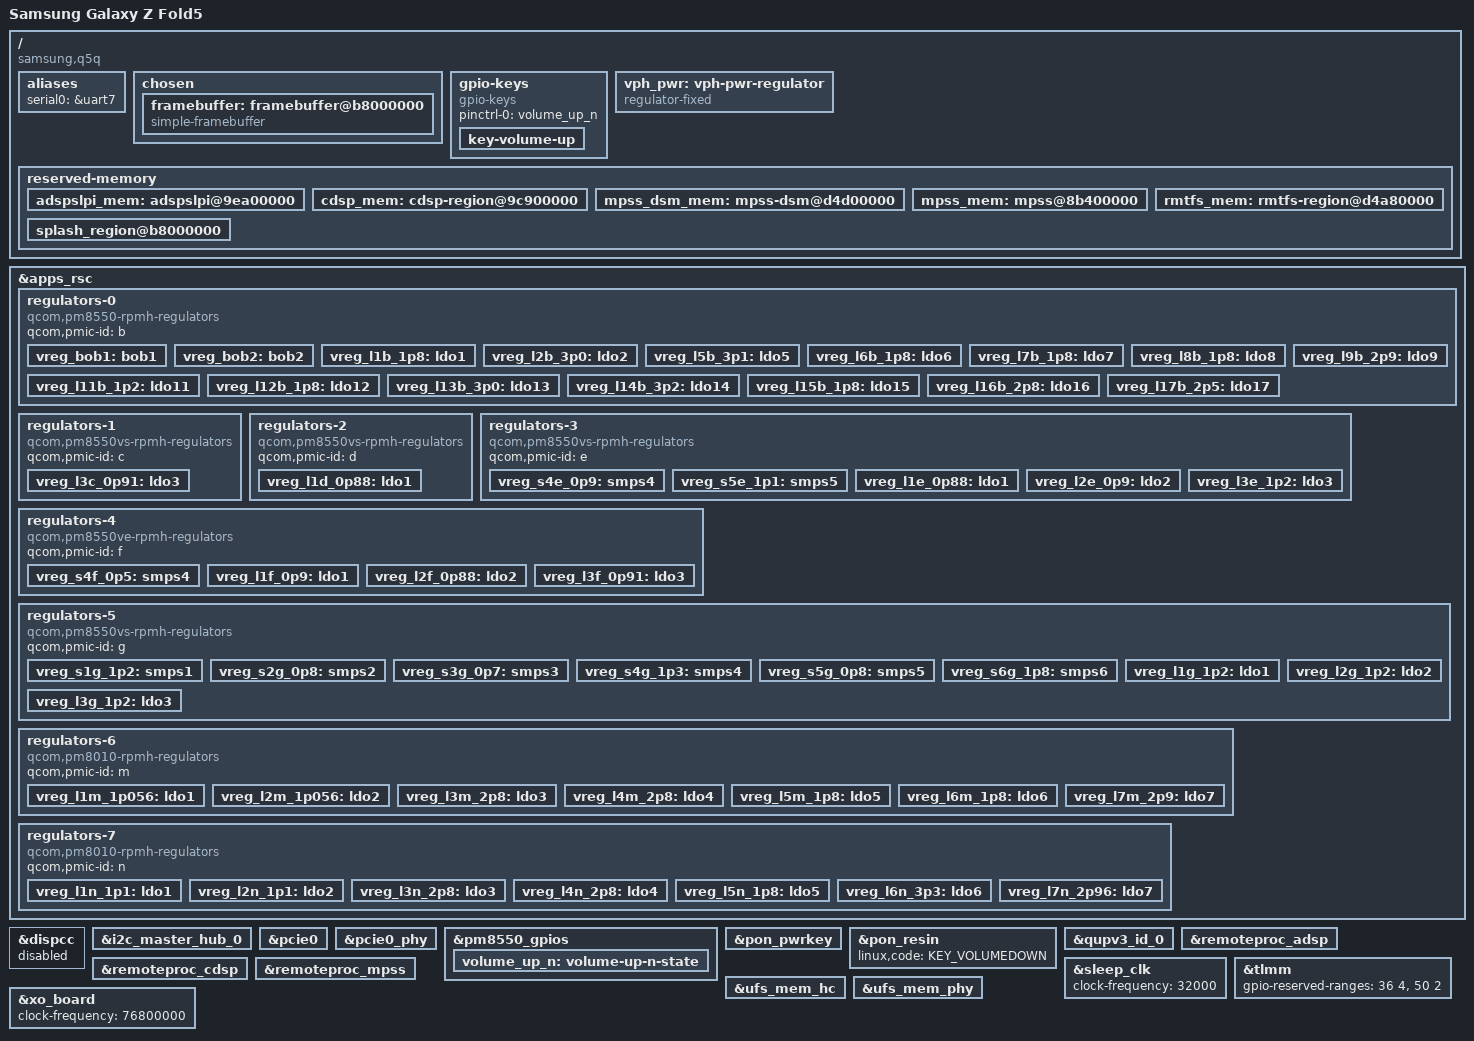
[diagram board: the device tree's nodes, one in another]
// SPDX-License-Identifier: BSD-3-Clause
/*
 * Copyright (c) 2024, Alexandru Marc Serdeliuc <serdeliuk@yahoo.com>
 * Copyright (c) 2024, David Wronek <david@mainlining.org>
 * Copyright (c) 2022, Linaro Limited
 */

/dts-v1/;

#include <dt-bindings/pinctrl/qcom,pmic-gpio.h>
#include <dt-bindings/regulator/qcom,rpmh-regulator.h>
#include "sm8550.dtsi"
#include "pm8550.dtsi"
#include "pm8550vs.dtsi"
#include "pmk8550.dtsi"

/delete-node/ &adspslpi_mem;
/delete-node/ &cdsp_mem;
/delete-node/ &mpss_dsm_mem;
/delete-node/ &mpss_mem;
/delete-node/ &rmtfs_mem;

/ {
	model = "Samsung Galaxy Z Fold5";
	compatible = "samsung,q5q", "qcom,sm8550";
	chassis-type = "handset";

	aliases {
		serial0 = &uart7;
	};

	chosen {
		#address-cells = <2>;
		#size-cells = <2>;
		ranges;

		framebuffer: framebuffer@b8000000 {
			compatible = "simple-framebuffer";
			reg = <0x0 0xb8000000 0x0 0x2b00000>;
			width = <2176>;
			height = <1812>;
			stride = <(2176 * 4)>;
			format = "a8r8g8b8";
		};
	};

	gpio-keys {
		compatible = "gpio-keys";
		pinctrl-0 = <&volume_up_n>;
		pinctrl-names = "default";

		key-volume-up {
			label = "Volume Up";
			linux,code = <KEY_VOLUMEUP>;
			gpios = <&pm8550_gpios 6 GPIO_ACTIVE_LOW>;
			debounce-interval = <15>;
			linux,can-disable;
			wakeup-source;
		};
	};

	vph_pwr: vph-pwr-regulator {
		compatible = "regulator-fixed";
		regulator-name = "vph_pwr";
		regulator-min-microvolt = <3700000>;
		regulator-max-microvolt = <3700000>;
		regulator-always-on;
		regulator-boot-on;
	};

	reserved-memory {
		adspslpi_mem: adspslpi@9ea00000 {
			reg = <0x0 0x9ea00000 0x0 0x59b4000>;
			no-map;
		};

		cdsp_mem: cdsp-region@9c900000 {
			reg = <0 0x9c900000 0 0x2000000>;
			no-map;
		};

		mpss_dsm_mem: mpss-dsm@d4d00000 {
			reg = <0x0 0xd4d00000 0x0 0x3300000>;
			no-map;
		};

		mpss_mem: mpss@8b400000 {
			reg = <0x0 0x8b400000 0x0 0xfc00000>;
			no-map;
		};

		rmtfs_mem: rmtfs-region@d4a80000 {
			reg = <0x0 0xd4a80000 0x0 0x280000>;
			no-map;
		};

		/*
		 * The bootloader will only keep display hardware enabled
		 * if this memory region is named exactly 'splash_region'
		 */
		splash_region@b8000000 {
			reg = <0x0 0xb8000000 0x0 0x2b00000>;
			no-map;
		};
	};
};

&apps_rsc {
	regulators-0 {
		compatible = "qcom,pm8550-rpmh-regulators";
		qcom,pmic-id = "b";

		vreg_bob1: bob1 {
			regulator-name = "vreg_bob1";
			regulator-min-microvolt = <3296000>;
			regulator-max-microvolt = <3960000>;
			regulator-initial-mode = <RPMH_REGULATOR_MODE_HPM>;
		};

		vreg_bob2: bob2 {
			regulator-name = "vreg_bob2";
			regulator-min-microvolt = <2720000>;
			regulator-max-microvolt = <3960000>;
			regulator-initial-mode = <RPMH_REGULATOR_MODE_HPM>;
		};

		vreg_l1b_1p8: ldo1 {
			regulator-name = "vreg_l1b_1p8";
			regulator-min-microvolt = <1800000>;
			regulator-max-microvolt = <1800000>;
			regulator-initial-mode = <RPMH_REGULATOR_MODE_HPM>;
		};

		vreg_l2b_3p0: ldo2 {
			regulator-name = "vreg_l2b_3p0";
			regulator-min-microvolt = <3008000>;
			regulator-max-microvolt = <3008000>;
			regulator-initial-mode = <RPMH_REGULATOR_MODE_HPM>;
		};

		vreg_l5b_3p1: ldo5 {
			regulator-name = "vreg_l5b_3p1";
			regulator-min-microvolt = <3104000>;
			regulator-max-microvolt = <3104000>;
			regulator-initial-mode = <RPMH_REGULATOR_MODE_HPM>;
		};

		vreg_l6b_1p8: ldo6 {
			regulator-name = "vreg_l6b_1p8";
			regulator-min-microvolt = <1800000>;
			regulator-max-microvolt = <3008000>;
			regulator-initial-mode = <RPMH_REGULATOR_MODE_HPM>;
		};

		vreg_l7b_1p8: ldo7 {
			regulator-name = "vreg_l7b_1p8";
			regulator-min-microvolt = <1800000>;
			regulator-max-microvolt = <3008000>;
			regulator-initial-mode = <RPMH_REGULATOR_MODE_HPM>;
		};

		vreg_l8b_1p8: ldo8 {
			regulator-name = "vreg_l8b_1p8";
			regulator-min-microvolt = <1800000>;
			regulator-max-microvolt = <3008000>;
			regulator-initial-mode = <RPMH_REGULATOR_MODE_HPM>;
		};

		vreg_l9b_2p9: ldo9 {
			regulator-name = "vreg_l9b_2p9";
			regulator-min-microvolt = <2960000>;
			regulator-max-microvolt = <3008000>;
			regulator-initial-mode = <RPMH_REGULATOR_MODE_HPM>;
		};

		vreg_l11b_1p2: ldo11 {
			regulator-name = "vreg_l11b_1p2";
			regulator-min-microvolt = <1200000>;
			regulator-max-microvolt = <1504000>;
			regulator-initial-mode = <RPMH_REGULATOR_MODE_HPM>;
		};

		vreg_l12b_1p8: ldo12 {
			regulator-name = "vreg_l12b_1p8";
			regulator-min-microvolt = <1800000>;
			regulator-max-microvolt = <1800000>;
			regulator-initial-mode = <RPMH_REGULATOR_MODE_HPM>;
		};

		vreg_l13b_3p0: ldo13 {
			regulator-name = "vreg_l13b_3p0";
			regulator-min-microvolt = <3000000>;
			regulator-max-microvolt = <3000000>;
			regulator-initial-mode = <RPMH_REGULATOR_MODE_HPM>;
		};

		vreg_l14b_3p2: ldo14 {
			regulator-name = "vreg_l14b_3p2";
			regulator-min-microvolt = <3200000>;
			regulator-max-microvolt = <3200000>;
			regulator-initial-mode = <RPMH_REGULATOR_MODE_HPM>;
		};

		vreg_l15b_1p8: ldo15 {
			regulator-name = "vreg_l15b_1p8";
			regulator-min-microvolt = <1800000>;
			regulator-max-microvolt = <1800000>;
			regulator-initial-mode = <RPMH_REGULATOR_MODE_HPM>;
			regulator-allow-set-load;
			regulator-allowed-modes = <RPMH_REGULATOR_MODE_LPM
						   RPMH_REGULATOR_MODE_HPM>;
			regulator-always-on;
		};

		vreg_l16b_2p8: ldo16 {
			regulator-name = "vreg_l16b_2p8";
			regulator-min-microvolt = <2800000>;
			regulator-max-microvolt = <2800000>;
			regulator-initial-mode = <RPMH_REGULATOR_MODE_HPM>;
		};

		vreg_l17b_2p5: ldo17 {
			regulator-name = "vreg_l17b_2p5";
			regulator-min-microvolt = <2504000>;
			regulator-max-microvolt = <2504000>;
			regulator-initial-mode = <RPMH_REGULATOR_MODE_HPM>;
		};
	};

	regulators-1 {
		compatible = "qcom,pm8550vs-rpmh-regulators";
		qcom,pmic-id = "c";

		vreg_l3c_0p91: ldo3 {
			regulator-name = "vreg_l3c_0p9";
			regulator-min-microvolt = <880000>;
			regulator-max-microvolt = <912000>;
			regulator-initial-mode = <RPMH_REGULATOR_MODE_HPM>;
		};
	};

	regulators-2 {
		compatible = "qcom,pm8550vs-rpmh-regulators";
		qcom,pmic-id = "d";

		vreg_l1d_0p88: ldo1 {
			regulator-name = "vreg_l1d_0p88";
			regulator-min-microvolt = <880000>;
			regulator-max-microvolt = <920000>;
			regulator-initial-mode = <RPMH_REGULATOR_MODE_HPM>;
		};
	};

	regulators-3 {
		compatible = "qcom,pm8550vs-rpmh-regulators";
		qcom,pmic-id = "e";

		vreg_s4e_0p9: smps4 {
			regulator-name = "vreg_s4e_0p9";
			regulator-min-microvolt = <904000>;
			regulator-max-microvolt = <984000>;
			regulator-initial-mode = <RPMH_REGULATOR_MODE_HPM>;
		};

		vreg_s5e_1p1: smps5 {
			regulator-name = "vreg_s5e_1p1";
			regulator-min-microvolt = <1080000>;
			regulator-max-microvolt = <1120000>;
			regulator-initial-mode = <RPMH_REGULATOR_MODE_HPM>;
		};

		vreg_l1e_0p88: ldo1 {
			regulator-name = "vreg_l1e_0p88";
			regulator-min-microvolt = <880000>;
			regulator-max-microvolt = <880000>;
			regulator-initial-mode = <RPMH_REGULATOR_MODE_HPM>;
		};

		vreg_l2e_0p9: ldo2 {
			regulator-name = "vreg_l2e_0p9";
			regulator-min-microvolt = <904000>;
			regulator-max-microvolt = <970000>;
			regulator-initial-mode = <RPMH_REGULATOR_MODE_HPM>;
		};

		vreg_l3e_1p2: ldo3 {
			regulator-name = "vreg_l3e_1p2";
			regulator-min-microvolt = <1200000>;
			regulator-max-microvolt = <1200000>;
			regulator-initial-mode = <RPMH_REGULATOR_MODE_HPM>;
		};
	};

	regulators-4 {
		compatible = "qcom,pm8550ve-rpmh-regulators";
		qcom,pmic-id = "f";

		vreg_s4f_0p5: smps4 {
			regulator-name = "vreg_s4f_0p5";
			regulator-min-microvolt = <500000>;
			regulator-max-microvolt = <700000>;
			regulator-initial-mode = <RPMH_REGULATOR_MODE_HPM>;
		};

		vreg_l1f_0p9: ldo1 {
			regulator-name = "vreg_l1f_0p9";
			regulator-min-microvolt = <912000>;
			regulator-max-microvolt = <912000>;
			regulator-initial-mode = <RPMH_REGULATOR_MODE_HPM>;
		};

		vreg_l2f_0p88: ldo2 {
			regulator-name = "vreg_l2f_0p88";
			regulator-min-microvolt = <880000>;
			regulator-max-microvolt = <912000>;
			regulator-initial-mode = <RPMH_REGULATOR_MODE_HPM>;
		};

		vreg_l3f_0p91: ldo3 {
			regulator-name = "vreg_l3f_0p91";
			regulator-min-microvolt = <880000>;
			regulator-max-microvolt = <912000>;
			regulator-initial-mode = <RPMH_REGULATOR_MODE_HPM>;
		};
	};

	regulators-5 {
		compatible = "qcom,pm8550vs-rpmh-regulators";
		qcom,pmic-id = "g";

		vreg_s1g_1p2: smps1 {
			regulator-name = "vreg_s1g_1p2";
			regulator-min-microvolt = <1200000>;
			regulator-max-microvolt = <1300000>;
			regulator-initial-mode = <RPMH_REGULATOR_MODE_HPM>;
		};

		vreg_s2g_0p8: smps2 {
			regulator-name = "vreg_s2g_0p8";
			regulator-min-microvolt = <800000>;
			regulator-max-microvolt = <1000000>;
			regulator-initial-mode = <RPMH_REGULATOR_MODE_HPM>;
		};

		vreg_s3g_0p7: smps3 {
			regulator-name = "vreg_s3g_0p7";
			regulator-min-microvolt = <300000>;
			regulator-max-microvolt = <1004000>;
			regulator-initial-mode = <RPMH_REGULATOR_MODE_HPM>;
		};

		vreg_s4g_1p3: smps4 {
			regulator-name = "vreg_s4g_1p3";
			regulator-min-microvolt = <1200000>;
			regulator-max-microvolt = <1352000>;
			regulator-initial-mode = <RPMH_REGULATOR_MODE_HPM>;
		};

		vreg_s5g_0p8: smps5 {
			regulator-name = "vreg_s5g_0p8";
			regulator-min-microvolt = <500000>;
			regulator-max-microvolt = <1004000>;
			regulator-initial-mode = <RPMH_REGULATOR_MODE_HPM>;
		};

		vreg_s6g_1p8: smps6 {
			regulator-name = "vreg_s6g_1p8";
			regulator-min-microvolt = <1800000>;
			regulator-max-microvolt = <2000000>;
			regulator-initial-mode = <RPMH_REGULATOR_MODE_HPM>;
		};

		vreg_l1g_1p2: ldo1 {
			regulator-name = "vreg_l1g_1p2";
			regulator-min-microvolt = <1200000>;
			regulator-max-microvolt = <1200000>;
			regulator-initial-mode = <RPMH_REGULATOR_MODE_HPM>;
		};

		vreg_l2g_1p2: ldo2 {
			regulator-name = "vreg_l2g_1p2";
			regulator-min-microvolt = <1200000>;
			regulator-max-microvolt = <1200000>;
			regulator-initial-mode = <RPMH_REGULATOR_MODE_HPM>;
		};

		vreg_l3g_1p2: ldo3 {
			regulator-name = "vreg_l3g_1p2";
			regulator-min-microvolt = <1200000>;
			regulator-max-microvolt = <1200000>;
			regulator-initial-mode = <RPMH_REGULATOR_MODE_HPM>;
		};
	};

	regulators-6 {
		compatible = "qcom,pm8010-rpmh-regulators";
		qcom,pmic-id = "m";

		vreg_l1m_1p056: ldo1 {
			regulator-name = "vreg_l1m_1p056";
			regulator-min-microvolt = <1056000>;
			regulator-max-microvolt = <1056000>;
			regulator-initial-mode = <RPMH_REGULATOR_MODE_HPM>;
		};

		vreg_l2m_1p056: ldo2 {
			regulator-name = "vreg_l2m_1p056";
			regulator-min-microvolt = <1056000>;
			regulator-max-microvolt = <1056000>;
			regulator-initial-mode = <RPMH_REGULATOR_MODE_HPM>;
		};

		vreg_l3m_2p8: ldo3 {
			regulator-name = "vreg_l3m_2p8";
			regulator-min-microvolt = <2800000>;
			regulator-max-microvolt = <2800000>;
			regulator-initial-mode = <RPMH_REGULATOR_MODE_HPM>;
		};

		vreg_l4m_2p8: ldo4 {
			regulator-name = "vreg_l4m_2p8";
			regulator-min-microvolt = <2800000>;
			regulator-max-microvolt = <2800000>;
			regulator-initial-mode = <RPMH_REGULATOR_MODE_HPM>;
		};

		vreg_l5m_1p8: ldo5 {
			regulator-name = "vreg_l5m_1p8";
			regulator-min-microvolt = <1800000>;
			regulator-max-microvolt = <1800000>;
			regulator-initial-mode = <RPMH_REGULATOR_MODE_HPM>;
		};

		vreg_l6m_1p8: ldo6 {
			regulator-name = "vreg_l6m_1p8";
			regulator-min-microvolt = <1800000>;
			regulator-max-microvolt = <1800000>;
			regulator-initial-mode = <RPMH_REGULATOR_MODE_HPM>;
		};

		vreg_l7m_2p9: ldo7 {
			regulator-name = "vreg_l7m_2p9";
			regulator-min-microvolt = <2800000>;
			regulator-max-microvolt = <2904000>;
			regulator-initial-mode = <RPMH_REGULATOR_MODE_HPM>;
		};
	};

	regulators-7 {
		compatible = "qcom,pm8010-rpmh-regulators";
		qcom,pmic-id = "n";

		vreg_l1n_1p1: ldo1 {
			regulator-name = "vreg_l1n_1p1";
			regulator-min-microvolt = <1104000>;
			regulator-max-microvolt = <1200000>;
			regulator-initial-mode = <RPMH_REGULATOR_MODE_HPM>;
		};

		vreg_l2n_1p1: ldo2 {
			regulator-name = "vreg_l2n_1p1";
			regulator-min-microvolt = <1104000>;
			regulator-max-microvolt = <1200000>;
			regulator-initial-mode = <RPMH_REGULATOR_MODE_HPM>;
		};

		vreg_l3n_2p8: ldo3 {
			regulator-name = "vreg_l3n_2p8";
			regulator-min-microvolt = <2800000>;
			regulator-max-microvolt = <3000000>;
			regulator-initial-mode = <RPMH_REGULATOR_MODE_HPM>;
		};

		vreg_l4n_2p8: ldo4 {
			regulator-name = "vreg_l4n_2p8";
			regulator-min-microvolt = <2800000>;
			regulator-max-microvolt = <3300000>;
			regulator-initial-mode = <RPMH_REGULATOR_MODE_HPM>;
		};

		vreg_l5n_1p8: ldo5 {
			regulator-name = "vreg_l5n_1p8";
			regulator-min-microvolt = <1800000>;
			regulator-max-microvolt = <1800000>;
			regulator-initial-mode = <RPMH_REGULATOR_MODE_HPM>;
		};

		vreg_l6n_3p3: ldo6 {
			regulator-name = "vreg_l6n_3p3";
			regulator-min-microvolt = <2800000>;
			regulator-max-microvolt = <3304000>;
			regulator-initial-mode = <RPMH_REGULATOR_MODE_HPM>;
		};

		vreg_l7n_2p96: ldo7 {
			regulator-name = "vreg_l7n_2p96";
			regulator-min-microvolt = <2800000>;
			regulator-max-microvolt = <2960000>;
			regulator-initial-mode = <RPMH_REGULATOR_MODE_HPM>;
		};
	};
};

&dispcc {
	status = "disabled";
};

&i2c_master_hub_0 {
	status = "okay";
};

&pcie0 {
	wake-gpios = <&tlmm 96 GPIO_ACTIVE_HIGH>;
	perst-gpios = <&tlmm 94 GPIO_ACTIVE_LOW>;
	pinctrl-0 = <&pcie0_default_state>;
	pinctrl-names = "default";
	status = "okay";
};

&pcie0_phy {
	vdda-phy-supply = <&vreg_l1e_0p88>;
	vdda-pll-supply = <&vreg_l3e_1p2>;
	status = "okay";
};

&pm8550_gpios {
	volume_up_n: volume-up-n-state {
		pins = "gpio6";
		function = "normal";
		power-source = <1>;
		bias-pull-up;
		input-enable;
	};
};

&pon_pwrkey {
	status = "okay";
};

&pon_resin {
	status = "okay";
	linux,code = <KEY_VOLUMEDOWN>;
};

&qupv3_id_0 {
	status = "okay";
};

&remoteproc_adsp {
	firmware-name = "qcom/sm8550/adsp.mdt",
			"qcom/sm8550/adsp_dtb.mdt";
	status = "okay";
};

&remoteproc_cdsp {
	firmware-name = "qcom/sm8550/cdsp.mdt",
			"qcom/sm8550/cdsp_dtb.mdt";
	status = "okay";
};

&remoteproc_mpss {
	firmware-name = "qcom/sm8550/modem.mdt",
			"qcom/sm8550/modem_dtb.mdt";
	status = "okay";
};

&sleep_clk {
	clock-frequency = <32000>;
};

&tlmm {
	gpio-reserved-ranges = <36 4>, <50 2>;
};

&ufs_mem_hc {
	reset-gpios = <&tlmm 210 GPIO_ACTIVE_LOW>;
	vcc-supply = <&vreg_l17b_2p5>;
	vcc-max-microamp = <1300000>;
	vccq-supply = <&vreg_l1g_1p2>;
	vccq-max-microamp = <1200000>;
	vdd-hba-supply = <&vreg_l3g_1p2>;
	status = "okay";
};

&ufs_mem_phy {
	vdda-phy-supply = <&vreg_l1d_0p88>;
	vdda-pll-supply = <&vreg_l3e_1p2>;
	status = "okay";
};

&xo_board {
	clock-frequency = <76800000>;
};
